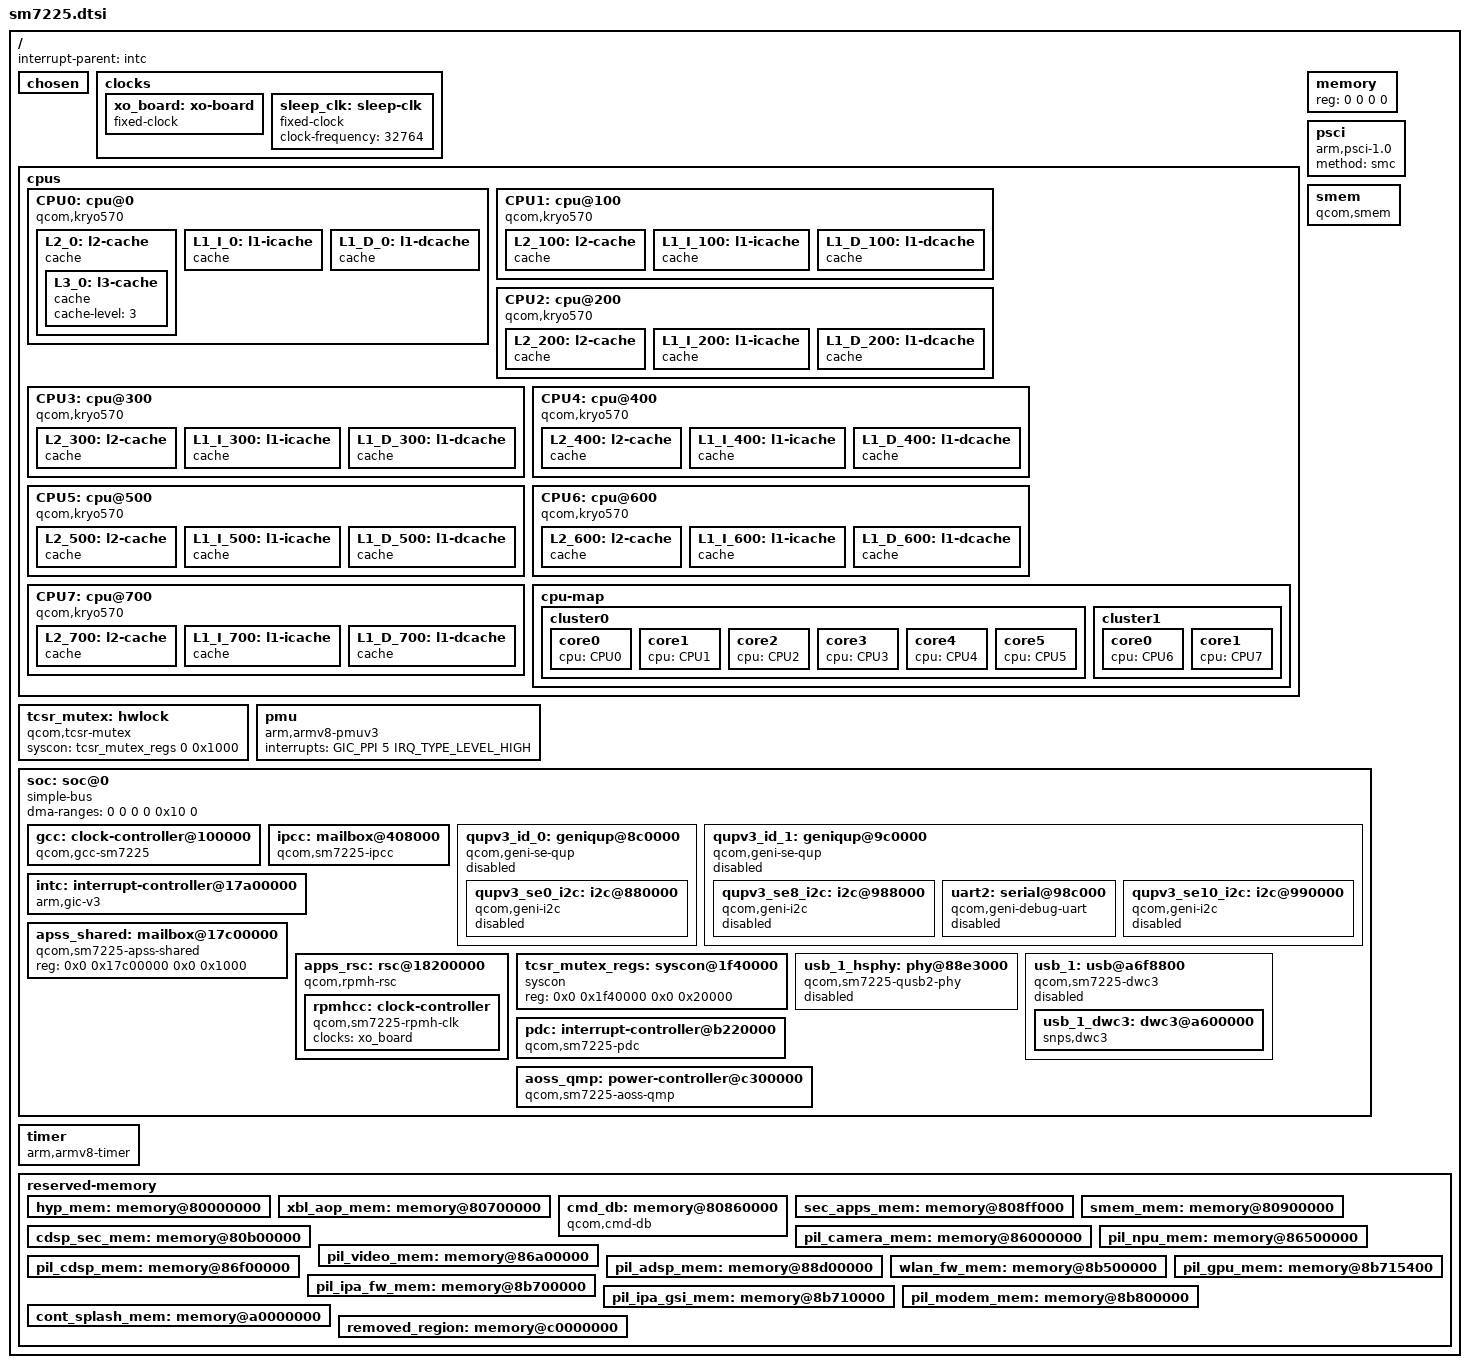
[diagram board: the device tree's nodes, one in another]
// SPDX-License-Identifier: BSD-3-Clause
/*
 * Copyright (c) 2021, Luca Weiss <luca@z3ntu.xyz>
 */

#include <dt-bindings/clock/qcom,gcc-sm7225.h>
#include <dt-bindings/clock/qcom,rpmh.h>
#include <dt-bindings/interrupt-controller/arm-gic.h>
#include <dt-bindings/mailbox/qcom-ipcc.h>
#include <dt-bindings/soc/qcom,rpmh-rsc.h>

/ {
	interrupt-parent = <&intc>;

	#address-cells = <2>;
	#size-cells = <2>;

	chosen { };

	clocks {
		xo_board: xo-board {
			compatible = "fixed-clock";
			#clock-cells = <0>;
			clock-frequency = <76800000>;
			clock-output-names = "xo_board";
		};

		sleep_clk: sleep-clk {
			compatible = "fixed-clock";
			clock-frequency = <32764>;
			#clock-cells = <0>;
		};
	};

	// TODO: qcom,freq-domain
	cpus {
		#address-cells = <2>;
		#size-cells = <0>;

		CPU0: cpu@0 {
			device_type = "cpu";
			compatible = "qcom,kryo570";
			reg = <0x0 0x0>;
			enable-method = "psci";
			capacity-dmips-mhz = <1024>;
			dynamic-power-coefficient = <100>;
			next-level-cache = <&L2_0>;
			#cooling-cells = <2>;
			L2_0: l2-cache {
				compatible = "cache";
				cache-level = <2>;
				next-level-cache = <&L3_0>;

				L3_0: l3-cache {
					compatible = "cache";
					cache-level = <3>;
				};
			};

			L1_I_0: l1-icache {
				compatible = "cache";
			};

			L1_D_0: l1-dcache {
				compatible = "cache";
			};
		};

		CPU1: cpu@100 {
			device_type = "cpu";
			compatible = "qcom,kryo570";
			reg = <0x0 0x100>;
			enable-method = "psci";
			capacity-dmips-mhz = <1024>;
			dynamic-power-coefficient = <100>;
			next-level-cache = <&L2_100>;
			#cooling-cells = <2>;
			L2_100: l2-cache {
				compatible = "cache";
				cache-level = <2>;
				next-level-cache = <&L3_0>;
			};

			L1_I_100: l1-icache {
				compatible = "cache";
			};

			L1_D_100: l1-dcache {
				compatible = "cache";
			};
		};

		CPU2: cpu@200 {
			device_type = "cpu";
			compatible = "qcom,kryo570";
			reg = <0x0 0x200>;
			enable-method = "psci";
			capacity-dmips-mhz = <1024>;
			dynamic-power-coefficient = <100>;
			next-level-cache = <&L2_200>;
			#cooling-cells = <2>;
			L2_200: l2-cache {
				compatible = "cache";
				cache-level = <2>;
				next-level-cache = <&L3_0>;
			};

			L1_I_200: l1-icache {
				compatible = "cache";
			};

			L1_D_200: l1-dcache {
				compatible = "cache";
			};
		};

		CPU3: cpu@300 {
			device_type = "cpu";
			compatible = "qcom,kryo570";
			reg = <0x0 0x300>;
			enable-method = "psci";
			capacity-dmips-mhz = <1024>;
			dynamic-power-coefficient = <100>;
			next-level-cache = <&L2_300>;
			#cooling-cells = <2>;
			L2_300: l2-cache {
				compatible = "cache";
				cache-level = <2>;
				next-level-cache = <&L3_0>;
			};

			L1_I_300: l1-icache {
				compatible = "cache";
			};

			L1_D_300: l1-dcache {
				compatible = "cache";
			};

		};

		CPU4: cpu@400 {
			device_type = "cpu";
			compatible = "qcom,kryo570";
			reg = <0x0 0x400>;
			enable-method = "psci";
			capacity-dmips-mhz = <1024>;
			dynamic-power-coefficient = <100>;
			next-level-cache = <&L2_400>;
			#cooling-cells = <2>;
			L2_400: l2-cache {
				compatible = "cache";
				cache-level = <2>;
				next-level-cache = <&L3_0>;
			};

			L1_I_400: l1-icache {
				compatible = "cache";
			};

			L1_D_400: l1-dcache {
				compatible = "cache";
			};
		};

		CPU5: cpu@500 {
			device_type = "cpu";
			compatible = "qcom,kryo570";
			reg = <0x0 0x500>;
			enable-method = "psci";
			capacity-dmips-mhz = <1024>;
			dynamic-power-coefficient = <100>;
			next-level-cache = <&L2_500>;
			#cooling-cells = <2>;
			L2_500: l2-cache {
				compatible = "cache";
				cache-level = <2>;
				next-level-cache = <&L3_0>;
			};

			L1_I_500: l1-icache {
				compatible = "cache";
			};

			L1_D_500: l1-dcache {
				compatible = "cache";
			};
		};

		CPU6: cpu@600 {
			device_type = "cpu";
			compatible = "qcom,kryo570";
			reg = <0x0 0x600>;
			enable-method = "psci";
			capacity-dmips-mhz = <1894>;
			dynamic-power-coefficient = <703>;
			next-level-cache = <&L2_600>;
			#cooling-cells = <2>;
			L2_600: l2-cache {
				compatible = "cache";
				cache-level = <2>;
				next-level-cache = <&L3_0>;
			};

			L1_I_600: l1-icache {
				compatible = "cache";
			};

			L1_D_600: l1-dcache {
				compatible = "cache";
			};
		};

		CPU7: cpu@700 {
			device_type = "cpu";
			compatible = "qcom,kryo570";
			reg = <0x0 0x700>;
			enable-method = "psci";
			capacity-dmips-mhz = <1894>;
			dynamic-power-coefficient = <703>;
			next-level-cache = <&L2_700>;
			#cooling-cells = <2>;
			L2_700: l2-cache {
				compatible = "cache";
				cache-level = <2>;
				next-level-cache = <&L3_0>;
			};

			L1_I_700: l1-icache {
				compatible = "cache";
			};

			L1_D_700: l1-dcache {
				compatible = "cache";
			};
		};

		cpu-map {
			/* Kryo Silver */
			cluster0 {
				core0 {
					cpu = <&CPU0>;
				};

				core1 {
					cpu = <&CPU1>;
				};

				core2 {
					cpu = <&CPU2>;
				};

				core3 {
					cpu = <&CPU3>;
				};

				core4 {
					cpu = <&CPU4>;
				};

				core5 {
					cpu = <&CPU5>;
				};
			};

			/* Kryo Gold */
			cluster1 {
				core0 {
					cpu = <&CPU6>;
				};

				core1 {
					cpu = <&CPU7>;
				};
			};

		};
	};

	tcsr_mutex: hwlock {
		compatible = "qcom,tcsr-mutex";
		syscon = <&tcsr_mutex_regs 0 0x1000>;
		#hwlock-cells = <1>;
	};

	memory {
		device_type = "memory";
		/* We expect the bootloader to fill in the size */
		reg = <0 0 0 0>;
	};

	pmu {
		compatible = "arm,armv8-pmuv3";
		interrupts = <GIC_PPI 5 IRQ_TYPE_LEVEL_HIGH>;
	};

	psci {
		compatible = "arm,psci-1.0";
		method = "smc";
	};

	smem {
		compatible = "qcom,smem";
		memory-region = <&smem_mem>;
		hwlocks = <&tcsr_mutex 3>;
	};

	soc: soc@0 {
		#address-cells = <2>;
		#size-cells = <2>;
		ranges = <0 0 0 0 0x10 0>;
		dma-ranges = <0 0 0 0 0x10 0>;
		compatible = "simple-bus";

		gcc: clock-controller@100000 {
			compatible = "qcom,gcc-sm7225";
			reg = <0x0 0x00100000 0x0 0x1f0000>;
			#clock-cells = <1>;
			#reset-cells = <1>;
			#power-domain-cells = <1>;
			clock-names = "bi_tcxo",
				      "bi_tcxo_ao",
				      "sleep_clk";
			clocks = <&rpmhcc RPMH_CXO_CLK>,
				 <&rpmhcc RPMH_CXO_CLK_A>,
				 <&sleep_clk>;
		};

		ipcc: mailbox@408000 {
			compatible = "qcom,sm7225-ipcc", "qcom,ipcc";
			reg = <0 0x00408000 0 0x1000>;
			interrupts = <GIC_SPI 228 IRQ_TYPE_LEVEL_HIGH>;
			interrupt-controller;
			#interrupt-cells = <3>;
			#mbox-cells = <2>;
		};

		qupv3_id_0: geniqup@8c0000 {
			compatible = "qcom,geni-se-qup";
			reg = <0x0 0x8c0000 0x0 0x2000>;
			clock-names = "m-ahb", "s-ahb";
			clocks = <&gcc GCC_QUPV3_WRAP_0_M_AHB_CLK>,
				 <&gcc GCC_QUPV3_WRAP_0_S_AHB_CLK>;
			#address-cells = <2>;
			#size-cells = <2>;
			// TODO iommus
			ranges;
			status = "disabled";

			// TODO qupv3_se0_i2c -> aw882xx_smartpa@34 & aw882xx_smartpa@35
			qupv3_se0_i2c: i2c@880000 {
				compatible = "qcom,geni-i2c";
				reg = <0 0x00880000 0 0x4000>;
				clock-names = "se";
				clocks = <&gcc GCC_QUPV3_WRAP0_S0_CLK>;
				//pinctrl-names = "default";
				//pinctrl-0 = <&qup_i2c0_default>;
				interrupts = <GIC_SPI 601 IRQ_TYPE_LEVEL_HIGH>;
				#address-cells = <1>;
				#size-cells = <0>;
				status = "disabled";
			};
		};

		qupv3_id_1: geniqup@9c0000 {
			compatible = "qcom,geni-se-qup";
			reg = <0x0 0x9c0000 0x0 0x2000>;
			clock-names = "m-ahb", "s-ahb";
			clocks = <&gcc GCC_QUPV3_WRAP_1_M_AHB_CLK>,
				 <&gcc GCC_QUPV3_WRAP_1_S_AHB_CLK>;
			#address-cells = <2>;
			#size-cells = <2>;
			// TODO iommus
			ranges;
			status = "disabled";

			// qupv3_se6_i2c: i2c@980000
			// qupv3_se7_i2c: i2c@984000

			// TODO qupv3_se8_i2c -> himax_ts@48
			qupv3_se8_i2c: i2c@988000 {
				compatible = "qcom,geni-i2c";
				reg = <0 0x00988000 0 0x4000>;
				clock-names = "se";
				clocks = <&gcc GCC_QUPV3_WRAP1_S2_CLK>;
				//pinctrl-names = "default";
				//pinctrl-0 = <&qup_i2c0_default>;
				interrupts = <GIC_SPI 355 IRQ_TYPE_LEVEL_HIGH>;
				#address-cells = <1>;
				#size-cells = <0>;
				status = "disabled";
			};

			uart2: serial@98c000 {
				compatible = "qcom,geni-debug-uart";
				reg = <0 0x98c000 0 0x4000>;
				clock-names = "se";
				clocks = <&gcc GCC_QUPV3_WRAP1_S3_CLK>;
				//pinctrl-names = "default", "sleep";
				//pinctrl-0 = <&qupv3_se9_2uart_active>;
				//pinctrl-1 = <&qupv3_se9_2uart_sleep>;
				interrupts = <GIC_SPI 356 IRQ_TYPE_LEVEL_HIGH>;
				#address-cells = <1>;
				#size-cells = <0>;
				status = "disabled";
			};

			// TODO qupv3_se10_i2c -> aw8695_haptic@5A
			qupv3_se10_i2c: i2c@990000 {
				compatible = "qcom,geni-i2c";
				reg = <0 0x00990000 0 0x4000>;
				clock-names = "se";
				clocks = <&gcc GCC_QUPV3_WRAP1_S4_CLK>;
				//pinctrl-names = "default";
				//pinctrl-0 = <&qup_i2c0_default>;
				interrupts = <GIC_SPI 357 IRQ_TYPE_LEVEL_HIGH>;
				#address-cells = <1>;
				#size-cells = <0>;
				status = "disabled";
			};
		};

		intc: interrupt-controller@17a00000 {
			compatible = "arm,gic-v3";
			#interrupt-cells = <3>;
			interrupt-controller;
			reg = <0x0 0x17a00000 0x0 0x10000>,	/* GICD */
			      <0x0 0x17a60000 0x0 0x100000>;	/* GICR * 8 */
			interrupts = <GIC_PPI 8 IRQ_TYPE_LEVEL_HIGH>;
		};

		apss_shared: mailbox@17c00000 {
			compatible = "qcom,sm7225-apss-shared";
			reg = <0x0 0x17c00000 0x0 0x1000>;
			#mbox-cells = <1>;
		};

		apps_rsc: rsc@18200000 {
			label = "apps_rsc";
			compatible = "qcom,rpmh-rsc";
			reg = <0x0 0x18200000 0x0 0x10000>,
			      <0x0 0x18210000 0x0 0x10000>,
			      <0x0 0x18220000 0x0 0x10000>;
			reg-names = "drv-0", "drv-1", "drv-2";
			interrupts = <GIC_SPI 3 IRQ_TYPE_LEVEL_HIGH>,
				     <GIC_SPI 4 IRQ_TYPE_LEVEL_HIGH>,
				     <GIC_SPI 5 IRQ_TYPE_LEVEL_HIGH>;
			qcom,tcs-offset = <0xd00>;
			qcom,drv-id = <2>;
			qcom,tcs-config = <ACTIVE_TCS  2>, <SLEEP_TCS   3>,
					  <WAKE_TCS    3>, <CONTROL_TCS 1>;

			rpmhcc: clock-controller {
				compatible = "qcom,sm7225-rpmh-clk";
				#clock-cells = <1>;
				clock-names = "xo";
				clocks = <&xo_board>;
			};

			// TODO rpmhpd

			// TODO apps_bcm_voter
		};

		tcsr_mutex_regs: syscon@1f40000 {
			compatible = "syscon";
			reg = <0x0 0x1f40000 0x0 0x20000>;
		};

		usb_1_hsphy: phy@88e3000 {
			compatible = "qcom,sm7225-qusb2-phy";
			reg = <0 0x088e3000 0 0x400>;
			status = "disabled";
			#phy-cells = <0>;

			clocks = <&rpmhcc RPMH_CXO_CLK>;
			clock-names = "ref";

			// VDD_USBHS_0P9 = DS vdd-supply &L18A
			// VDD_A_USBHS_1P8 = DS vdda18-supply &L2A
			// VDD_A_USBHS_3P1 = DS vdda33-supply &L3A
			//vdda-pll-supply = <>;
			//vdda-phy-dpdm-supply = <>;

			resets = <&gcc GCC_QUSB2PHY_PRIM_BCR>;
			// nvmem-cells = <&qusb2p_hstx_trim>; // USB tuning thing
		};

		//usb_1_qmpphy: phy@88e9000 {
		//	compatible = "qcom,sm7225-qmp-usb3-dp-phy";
		//	reg = <0 0x088e9000 0 0x200>,
		//	      <0 0x088e8000 0 0x40>,
		//	      <0 0x088ea000 0 0x200>;
		//	reg-names = "usb", "dp_com", "dp";
		//	status = "disabled";
		//	#address-cells = <2>;
		//	#size-cells = <2>;
		//	ranges;

		//	clocks = <&gcc GCC_USB3_PRIM_PHY_AUX_CLK>,
		//		 <&rpmhcc RPMH_CXO_CLK>,
		//		 <&gcc GCC_USB3_PRIM_PHY_COM_AUX_CLK>;
		//	clock-names = "aux", "ref_clk_src", "com_aux";

		//	resets = <&gcc GCC_USB3_DP_PHY_PRIM_BCR>,
		//		 <&gcc GCC_USB3_PHY_PRIM_BCR>;
		//	reset-names = "phy", "common";

		//	usb_1_ssphy: usb3-phy@88e9200 {
		//		reg = <0 0x088e9200 0 0x200>,
		//		      <0 0x088e9400 0 0x200>,
		//		      <0 0x088e9c00 0 0x400>,
		//		      <0 0x088e9600 0 0x200>,
		//		      <0 0x088e9800 0 0x200>,
		//		      <0 0x088e9a00 0 0x100>;
		//		#clock-cells = <0>;
		//		#phy-cells = <0>;
		//		clocks = <&gcc GCC_USB3_PRIM_PHY_PIPE_CLK>;
		//		clock-names = "pipe0";
		//		clock-output-names = "usb3_phy_pipe_clk_src";
		//	};

		//	dp_phy: dp-phy@88ea200 {
		//		reg = <0 0x088ea200 0 0x200>,
		//		      <0 0x088ea400 0 0x200>,
		//		      <0 0x088eac00 0 0x400>,
		//		      <0 0x088ea600 0 0x200>,
		//		      <0 0x088ea800 0 0x200>,
		//		      <0 0x088eaa00 0 0x100>;
		//		#phy-cells = <0>;
		//		#clock-cells = <1>;
		//		clocks = <&gcc GCC_USB3_PRIM_PHY_PIPE_CLK>;
		//		clock-names = "pipe0";
		//		clock-output-names = "usb3_phy_pipe_clk_src";
		//	};
		//};

		usb_1: usb@a6f8800 {
			compatible = "qcom,sm7225-dwc3", "qcom,dwc3";
			reg = <0 0x0a6f8800 0 0x400>;
			status = "disabled";
			#address-cells = <2>;
			#size-cells = <2>;
			ranges;
			dma-ranges;

			clocks = <&gcc GCC_CFG_NOC_USB3_PRIM_AXI_CLK>,
				 <&gcc GCC_USB30_PRIM_MASTER_CLK>,
				 <&gcc GCC_AGGRE_USB3_PRIM_AXI_CLK>,
				 <&gcc GCC_USB30_PRIM_MOCK_UTMI_CLK>,
				 <&gcc GCC_USB30_PRIM_SLEEP_CLK>,
				 <&gcc GCC_USB3_PRIM_CLKREF_CLK>;
			clock-names = "cfg_noc", "core", "iface", "mock_utmi",
				      "sleep", "xo";

			assigned-clocks = <&gcc GCC_USB30_PRIM_MOCK_UTMI_CLK>,
					  <&gcc GCC_USB30_PRIM_MASTER_CLK>;
			assigned-clock-rates = <19200000>, <133333333>;

			interrupts-extended = <&intc GIC_SPI 130 IRQ_TYPE_LEVEL_HIGH>,
					      <&pdc 14 IRQ_TYPE_EDGE_BOTH>,
					      <&pdc 15 IRQ_TYPE_EDGE_BOTH>,
					      <&pdc 17 IRQ_TYPE_LEVEL_HIGH>;
			interrupt-names = "hs_phy_irq", "dp_hs_phy_irq",
					  "dm_hs_phy_irq", "ss_phy_irq";

			power-domains = <&gcc GCC_USB30_PRIM_GDSC>;

			resets = <&gcc GCC_USB30_PRIM_BCR>;

			/* High-speed USB only for now */
			qcom,select-utmi-as-pipe-clk;

			usb_1_dwc3: dwc3@a600000 {
				compatible = "snps,dwc3";
				reg = <0 0x0a600000 0 0xe000>;
				interrupts = <GIC_SPI 133 IRQ_TYPE_LEVEL_HIGH>;
				// iommus = <&apps_smmu 0x540 0x0>; // FIXME
				// snps,disable-clk-gating;
				snps,dis_u2_susphy_quirk;
				snps,dis_enblslpm_quirk;
				snps,has-lpm-erratum;
				snps,hird-threshold = /bits/ 8 <0x10>;
				//snps,usb3-u1u2-disable;
				snps,dis-u1-entry-quirk;
				snps,dis-u2-entry-quirk;
				// ^^
				//usb-core-id = <0>;
				tx-fifo-resize;
				phys = <&usb_1_hsphy>; //, <&usb_1_ssphy>;
				phy-names = "usb2-phy"; //, usb3-phy;
			};
		};

		pdc: interrupt-controller@b220000 {
			compatible = "qcom,sm7225-pdc", "qcom,pdc";
			reg = <0 0xb220000 0 0x30000>, <0 0x17c000f0 0 0x64>;
			qcom,pdc-ranges = <0 480 94>, <94 609 31>, <125 63 1>,
					  <126 655 12>, <138 139 15>;
			#interrupt-cells = <2>;
			interrupt-parent = <&intc>;
			interrupt-controller;
		};

		aoss_qmp: power-controller@c300000 {
			compatible = "qcom,sm7225-aoss-qmp";
			reg = <0x0 0xc300000 0x0 0x1000>;
			interrupts-extended = <&ipcc IPCC_CLIENT_AOP
						     IPCC_MPROC_SIGNAL_GLINK_QMP
						     IRQ_TYPE_EDGE_RISING>;
			mboxes = <&ipcc IPCC_CLIENT_AOP IPCC_MPROC_SIGNAL_GLINK_QMP>;

			#clock-cells = <0>;
			#power-domain-cells = <1>;
		};
	};

	timer {
		compatible = "arm,armv8-timer";
		interrupts = <GIC_PPI 1 (GIC_CPU_MASK_SIMPLE(8) | IRQ_TYPE_LEVEL_LOW)>,
			     <GIC_PPI 2 (GIC_CPU_MASK_SIMPLE(8) | IRQ_TYPE_LEVEL_LOW)>,
			     <GIC_PPI 3 (GIC_CPU_MASK_SIMPLE(8) | IRQ_TYPE_LEVEL_LOW)>,
			     <GIC_PPI 0 (GIC_CPU_MASK_SIMPLE(8) | IRQ_TYPE_LEVEL_LOW)>;
	};

	reserved-memory {
		#address-cells = <2>;
		#size-cells = <2>;
		ranges;

		hyp_mem: memory@80000000 {
			reg = <0x0 0x80000000 0x0 0x600000>;
			no-map;
		};

		xbl_aop_mem: memory@80700000 {
			reg = <0x0 0x80700000 0x0 0x160000>;
			no-map;
		};

		cmd_db: memory@80860000 {
			compatible = "qcom,cmd-db";
			reg = <0x0 0x80860000 0x0 0x20000>;
			no-map;
		};

		sec_apps_mem: memory@808ff000 {
			reg = <0x0 0x808ff000 0x0 0x1000>;
			no-map;
		};

		smem_mem: memory@80900000 {
			reg = <0x0 0x80900000 0x0 0x200000>;
			no-map;
		};

		cdsp_sec_mem: memory@80b00000 {
			reg = <0x0 0x80b00000 0x0 0x1e00000>;
			no-map;
		};

		pil_camera_mem: memory@86000000 {
			reg = <0x0 0x86000000 0x0 0x500000>;
			no-map;
		};

		pil_npu_mem: memory@86500000 {
			reg = <0x0 0x86500000 0x0 0x500000>;
			no-map;
		};

		pil_video_mem: memory@86a00000 {
			reg = <0x0 0x86a00000 0x0 0x500000>;
			no-map;
		};

		pil_cdsp_mem: memory@86f00000 {
			reg = <0x0 0x86f00000 0x0 0x1e00000>;
			no-map;
		};

		pil_adsp_mem: memory@88d00000 {
			reg = <0x0 0x88d00000 0x0 0x2800000>;
			no-map;
		};

		wlan_fw_mem: memory@8b500000 {
			reg = <0x0 0x8b500000 0x0 0x200000>;
			no-map;
		};

		pil_ipa_fw_mem: memory@8b700000 {
			reg = <0x0 0x8b700000 0x0 0x10000>;
			no-map;
		};

		pil_ipa_gsi_mem: memory@8b710000 {
			reg = <0x0 0x8b710000 0x0 0x5400>;
			no-map;
		};

		pil_gpu_mem: memory@8b715400 {
			reg = <0x0 0x8b715400 0x0 0x2000>;
			no-map;
		};

		pil_modem_mem: memory@8b800000 {
			reg = <0x0 0x8b800000 0x0 0xf800000>;
			no-map;
		};

		cont_splash_mem: memory@a0000000 {
			reg = <0x0 0xa0000000 0x0 0x02300000>;
			no-map;
		};

		removed_region: memory@c0000000 {
			reg = <0x0 0xc0000000 0x0 0x3900000>;
			no-map;
		};
	};
};
